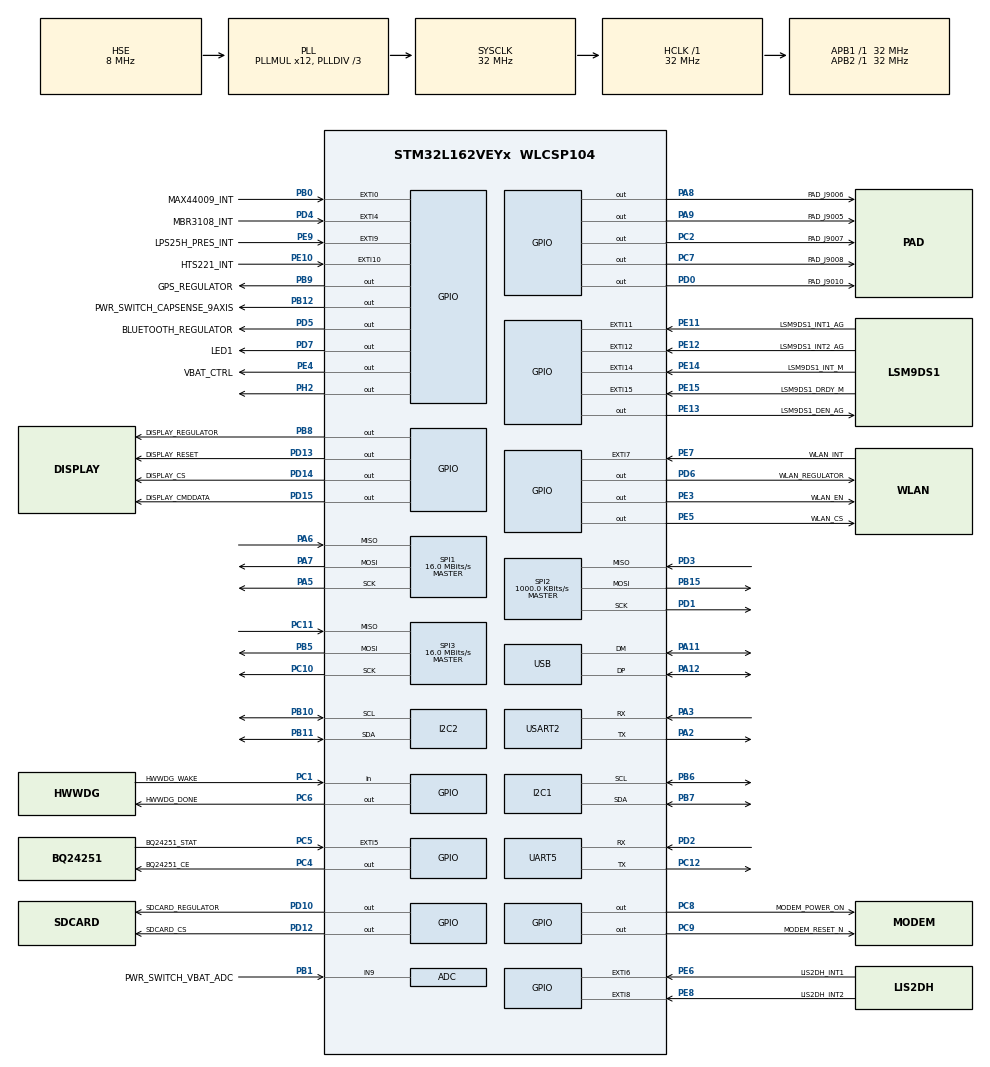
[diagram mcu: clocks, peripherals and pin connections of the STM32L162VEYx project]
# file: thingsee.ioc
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ADC.Channel-0\#ChannelRegularConversion=ADC_CHANNEL_9
ADC.NbrOfConversionFlag=1
ADC.Rank-0\#ChannelRegularConversion=1
ADC.SamplingTime-0\#ChannelRegularConversion=ADC_SAMPLETIME_4CYCLES
Mcu.Family=STM32L1
Mcu.Name=STM32L162VEYx
Mcu.Package=WLCSP104
NVIC.PriorityGroup=NVIC_PRIORITYGROUP_4
NVIC.USB_LP_IRQn=true\:0\:0\:false\:false\:true\:false
PA11.Mode=Device
PA11.Signal=USB_DM
PA12.Mode=Device
PA12.Signal=USB_DP
PA2.Mode=Asynchronous
PA2.Signal=USART2_TX
PA3.Mode=Asynchronous
PA3.Signal=USART2_RX
PA5.Mode=Full_Duplex_Master
PA5.Signal=SPI1_SCK
PA6.Mode=Full_Duplex_Master
PA6.Signal=SPI1_MISO
PA7.Mode=Full_Duplex_Master
PA7.Signal=SPI1_MOSI
PA8.GPIO_Label=PAD_J9006
PA8.GPIO_Speed=GPIO_SPEED_FREQ_HIGH
PA8.Signal=GPIO_Output
PA9.GPIO_Label=PAD_J9005
PA9.GPIO_Speed=GPIO_SPEED_FREQ_HIGH
PA9.Signal=GPIO_Output
PB0.GPIO_Label=MAX44009_INT
PB0.Signal=GPXTI0
PB1.GPIO_Label=PWR_SWITCH_VBAT_ADC
PB1.Mode=IN9
PB1.Signal=ADC_IN9
PB10.Mode=I2C
PB10.Signal=I2C2_SCL
PB11.Mode=I2C
PB11.Signal=I2C2_SDA
PB12.GPIO_Label=PWR_SWITCH_CAPSENSE_9AXIS
PB12.GPIO_Speed=GPIO_SPEED_FREQ_HIGH
PB12.Signal=GPIO_Output
PB15.Mode=Full_Duplex_Master
PB15.Signal=SPI2_MOSI
PB5.Mode=Full_Duplex_Master
PB5.Signal=SPI3_MOSI
PB6.Mode=I2C
PB6.Signal=I2C1_SCL
PB7.Mode=I2C
PB7.Signal=I2C1_SDA
PB8.GPIO_Label=DISPLAY_REGULATOR
PB8.GPIO_Speed=GPIO_SPEED_FREQ_HIGH
PB8.Signal=GPIO_Output
PB9.GPIO_Label=GPS_REGULATOR
PB9.GPIO_Speed=GPIO_SPEED_FREQ_HIGH
PB9.Signal=GPIO_Output
PC1.GPIO_Label=HWWDG_WAKE
PC1.Signal=GPIO_Input
PC10.Mode=Full_Duplex_Master
PC10.Signal=SPI3_SCK
PC11.Mode=Full_Duplex_Master
PC11.Signal=SPI3_MISO
PC12.Mode=Asynchronous
PC12.Signal=UART5_TX
PC14-OSC32_IN.Mode=LSE-External-Oscillator
PC14-OSC32_IN.Signal=RCC_OSC32_IN
PC15-OSC32_OUT.Mode=LSE-External-Oscillator
PC15-OSC32_OUT.Signal=RCC_OSC32_OUT
PC2.GPIO_Label=PAD_J9007
PC2.GPIO_Speed=GPIO_SPEED_FREQ_HIGH
PC2.Signal=GPIO_Output
PC4.GPIO_Label=BQ24251_CE
PC4.GPIO_Speed=GPIO_SPEED_FREQ_HIGH
PC4.Signal=GPIO_Output
PC5.GPIO_Label=BQ24251_STAT
PC5.Signal=GPXTI5
PC6.GPIO_Label=HWWDG_DONE
PC6.GPIO_Speed=GPIO_SPEED_FREQ_HIGH
PC6.Signal=GPIO_Output
PC7.GPIO_Label=PAD_J9008
PC7.GPIO_Speed=GPIO_SPEED_FREQ_HIGH
PC7.Signal=GPIO_Output
PC8.GPIO_Label=MODEM_POWER_ON
PC8.GPIO_ModeDefaultOutputPP=GPIO_MODE_OUTPUT_OD
PC8.GPIO_Speed=GPIO_SPEED_FREQ_HIGH
PC8.PinState=GPIO_PIN_SET
PC8.Signal=GPIO_Output
PC9.GPIO_Label=MODEM_RESET_N
PC9.GPIO_ModeDefaultOutputPP=GPIO_MODE_OUTPUT_OD
PC9.GPIO_Speed=GPIO_SPEED_FREQ_HIGH
PC9.PinState=GPIO_PIN_SET
PC9.Signal=GPIO_Output
PD0.GPIO_Label=PAD_J9010
PD0.GPIO_Speed=GPIO_SPEED_FREQ_HIGH
PD0.Signal=GPIO_Output
PD1.Mode=Full_Duplex_Master
PD1.Signal=SPI2_SCK
PD10.GPIO_Label=SDCARD_REGULATOR
PD10.GPIO_Speed=GPIO_SPEED_FREQ_HIGH
PD10.Signal=GPIO_Output
PD12.GPIO_Label=SDCARD_CS
PD12.GPIO_Speed=GPIO_SPEED_FREQ_HIGH
PD12.PinState=GPIO_PIN_SET
PD12.Signal=GPIO_Output
PD13.GPIO_Label=DISPLAY_RESET
PD13.GPIO_Speed=GPIO_SPEED_FREQ_HIGH
PD13.Signal=GPIO_Output
PD14.GPIO_Label=DISPLAY_CS
PD14.GPIO_Speed=GPIO_SPEED_FREQ_HIGH
PD14.PinState=GPIO_PIN_SET
PD14.Signal=GPIO_Output
PD15.GPIO_Label=DISPLAY_CMDDATA
PD15.GPIO_Speed=GPIO_SPEED_FREQ_HIGH
PD15.Signal=GPIO_Output
PD2.Mode=Asynchronous
PD2.Signal=UART5_RX
PD3.Mode=Full_Duplex_Master
PD3.Signal=SPI2_MISO
PD4.GPIO_Label=MBR3108_INT
PD4.Signal=GPXTI4
PD5.GPIO_Label=BLUETOOTH_REGULATOR
PD5.GPIO_Speed=GPIO_SPEED_FREQ_HIGH
PD5.Signal=GPIO_Output
PD6.GPIO_Label=WLAN_REGULATOR
PD6.GPIO_Speed=GPIO_SPEED_FREQ_HIGH
PD6.Signal=GPIO_Output
PD7.GPIO_Label=LED1
PD7.GPIO_Speed=GPIO_SPEED_FREQ_HIGH
PD7.Signal=GPIO_Output
PE10.GPIO_Label=HTS221_INT
PE10.Signal=GPXTI10
PE11.GPIO_Label=LSM9DS1_INT1_AG
PE11.Signal=GPXTI11
PE12.GPIO_Label=LSM9DS1_INT2_AG
PE12.Signal=GPXTI12
PE13.GPIO_Label=LSM9DS1_DEN_AG
PE13.GPIO_Speed=GPIO_SPEED_FREQ_HIGH
PE13.Signal=GPIO_Output
PE14.GPIO_Label=LSM9DS1_INT_M
PE14.Signal=GPXTI14
PE15.GPIO_Label=LSM9DS1_DRDY_M
PE15.Signal=GPXTI15
PE3.GPIO_Label=WLAN_EN
PE3.GPIO_Speed=GPIO_SPEED_FREQ_HIGH
PE3.Signal=GPIO_Output
PE4.GPIO_Label=VBAT_CTRL
PE4.GPIO_Speed=GPIO_SPEED_FREQ_HIGH
PE4.Signal=GPIO_Output
PE5.GPIO_Label=WLAN_CS
PE5.GPIO_Speed=GPIO_SPEED_FREQ_HIGH
PE5.PinState=GPIO_PIN_SET
PE5.Signal=GPIO_Output
PE6-WKUP3.GPIO_Label=LIS2DH_INT1
PE6-WKUP3.Signal=GPXTI6
PE7.GPIO_Label=WLAN_INT
PE7.Signal=GPXTI7
PE8.GPIO_Label=LIS2DH_INT2
PE8.Signal=GPXTI8
PE9.GPIO_Label=LPS25H_PRES_INT
PE9.Signal=GPXTI9
PH0-OSC_IN.Mode=HSE-External-Oscillator
PH0-OSC_IN.Signal=RCC_OSC_IN
PH1-OSC_OUT.Mode=HSE-External-Oscillator
PH1-OSC_OUT.Signal=RCC_OSC_OUT
PH2.GPIO_Speed=GPIO_SPEED_FREQ_HIGH
PH2.Signal=GPIO_Output
ProjectManager.HeapSize=0x200
ProjectManager.StackSize=0x400
ProjectManager.TargetToolchain=Makefile
RCC.48MHZClocksFreq_Value=48000000
RCC.AHBFreq_Value=32000000
RCC.APB1Freq_Value=32000000
RCC.APB1TimFreq_Value=32000000
RCC.APB2Freq_Value=32000000
RCC.APB2TimFreq_Value=32000000
RCC.HCLKFreq_Value=32000000
RCC.HSE_VALUE=8000000
RCC.HSI_VALUE=16000000
RCC.MSI_VALUE=2097000
RCC.PLLDIV=RCC_PLL_DIV3
RCC.PLLMUL=RCC_PLL_MUL12
RCC.SYSCLKFreq_VALUE=32000000
RCC.SYSCLKSource=RCC_SYSCLKSOURCE_PLLCLK
RCC.VCOOutputFreq_Value=96000000
SPI1.CalculateBaudRate=16.0 MBits/s
SPI1.Direction=SPI_DIRECTION_2LINES
SPI1.Mode=SPI_MODE_MASTER
SPI1.VirtualType=VM_MASTER
SPI2.BaudRatePrescaler=SPI_BAUDRATEPRESCALER_32
SPI2.CLKPhase=SPI_PHASE_1EDGE
SPI2.CLKPolarity=SPI_POLARITY_HIGH
SPI2.CalculateBaudRate=1000.0 KBits/s
SPI2.Direction=SPI_DIRECTION_2LINES
SPI2.Mode=SPI_MODE_MASTER
SPI2.VirtualType=VM_MASTER
SPI3.CalculateBaudRate=16.0 MBits/s
SPI3.Direction=SPI_DIRECTION_2LINES
SPI3.Mode=SPI_MODE_MASTER
SPI3.VirtualType=VM_MASTER
UART5.VirtualMode=Asynchronous
USART2.VirtualMode=VM_ASYNC
USB_DEVICE.CLASS_NAME_FS=CDC
USB_DEVICE.VirtualMode=Cdc
USB_DEVICE.VirtualModeFS=Cdc_FS
VP_ADC_TempSens_Input.Mode=IN-TempSens
VP_RTC_VS_RTC_Activate.Mode=RTC_Enabled
VP_USB_DEVICE_VS_USB_DEVICE_CDC_FS.Mode=CDC_FS
board=custom

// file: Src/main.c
/**
  ******************************************************************************
  * @file           : main.c
  * @brief          : Main program body
  ******************************************************************************
  * This notice applies to any and all portions of this file
  * that are not between comment pairs USER CODE BEGIN and
  * USER CODE END. Other portions of this file, whether
  * inserted by the user or by software development tools
  * are owned by their respective copyright owners.
  *
  * Copyright (c) 2018 STMicroelectronics International N.V.
  * All rights reserved.
  *
  * Redistribution and use in source and binary forms, with or without
  * modification, are permitted, provided that the following conditions are met:
  *
  * 1. Redistribution of source code must retain the above copyright notice,
  *    this list of conditions and the following disclaimer.
  * 2. Redistributions in binary form must reproduce the above copyright notice,
  *    this list of conditions and the following disclaimer in the documentation
  *    and/or other materials provided with the distribution.
  * 3. Neither the name of STMicroelectronics nor the names of other
  *    contributors to this software may be used to endorse or promote products
  *    derived from this software without specific written permission.
  * 4. This software, including modifications and/or derivative works of this
  *    software, must execute solely and exclusively on microcontroller or
  *    microprocessor devices manufactured by or for STMicroelectronics.
  * 5. Redistribution and use of this software other than as permitted under
  *    this license is void and will automatically terminate your rights under
  *    this license.
  *
  * THIS SOFTWARE IS PROVIDED BY STMICROELECTRONICS AND CONTRIBUTORS "AS IS"
  * AND ANY EXPRESS, IMPLIED OR STATUTORY WARRANTIES, INCLUDING, BUT NOT
  * LIMITED TO, THE IMPLIED WARRANTIES OF MERCHANTABILITY, FITNESS FOR A
  * PARTICULAR PURPOSE AND NON-INFRINGEMENT OF THIRD PARTY INTELLECTUAL PROPERTY
  * RIGHTS ARE DISCLAIMED TO THE FULLEST EXTENT PERMITTED BY LAW. IN NO EVENT
  * SHALL STMICROELECTRONICS OR CONTRIBUTORS BE LIABLE FOR ANY DIRECT, INDIRECT,
  * INCIDENTAL, SPECIAL, EXEMPLARY, OR CONSEQUENTIAL DAMAGES (INCLUDING, BUT NOT
  * LIMITED TO, PROCUREMENT OF SUBSTITUTE GOODS OR SERVICES; LOSS OF USE, DATA,
  * OR PROFITS; OR BUSINESS INTERRUPTION) HOWEVER CAUSED AND ON ANY THEORY OF
  * LIABILITY, WHETHER IN CONTRACT, STRICT LIABILITY, OR TORT (INCLUDING
  * NEGLIGENCE OR OTHERWISE) ARISING IN ANY WAY OUT OF THE USE OF THIS SOFTWARE,
  * EVEN IF ADVISED OF THE POSSIBILITY OF SUCH DAMAGE.
  *
  ******************************************************************************
  */
#include "main.h"
#include "stm32l1xx_hal.h"
#include "usb_device.h"

/* USER CODE BEGIN Includes */
#include "app.h"
/* USER CODE END Includes */

ADC_HandleTypeDef hadc;

I2C_HandleTypeDef hi2c1;
I2C_HandleTypeDef hi2c2;

RTC_HandleTypeDef hrtc;

SPI_HandleTypeDef hspi1;
SPI_HandleTypeDef hspi2;
SPI_HandleTypeDef hspi3;

UART_HandleTypeDef huart5;
UART_HandleTypeDef huart2;

/* USER CODE BEGIN PV */
/* Private variables ---------------------------------------------------------*/

/* USER CODE END PV */

void SystemClock_Config(void);
static void MX_GPIO_Init(void);
static void MX_ADC_Init(void);
static void MX_RTC_Init(void);
static void MX_I2C1_Init(void);
static void MX_I2C2_Init(void);
static void MX_USART2_UART_Init(void);
static void MX_UART5_Init(void);
static void MX_SPI2_Init(void);
static void MX_SPI1_Init(void);
static void MX_SPI3_Init(void);

/* USER CODE BEGIN PFP */
/* Private function prototypes -----------------------------------------------*/

/* USER CODE END PFP */

int main(void)
{

  /* MCU Configuration----------------------------------------------------------*/

  /* Reset of all peripherals, Initializes the Flash interface and the Systick. */
  HAL_Init();

  /* Configure the system clock */
  SystemClock_Config();

  /* Initialize all configured peripherals */
  MX_GPIO_Init();
  MX_ADC_Init();
  MX_RTC_Init();
  MX_USB_DEVICE_Init();
  MX_I2C1_Init();
  MX_I2C2_Init();
  MX_USART2_UART_Init();
  MX_UART5_Init();
  MX_SPI2_Init();
  MX_SPI1_Init();
  MX_SPI3_Init();
  /* USER CODE BEGIN 2 */

  setup();

  /* USER CODE END 2 */

  /* Infinite loop */
  while (1)
  {

  /* USER CODE BEGIN 3 */
    loop();
  }
  /* USER CODE END 3 */

}

void SystemClock_Config(void)
{

  RCC_OscInitTypeDef RCC_OscInitStruct;
  RCC_ClkInitTypeDef RCC_ClkInitStruct;
  RCC_PeriphCLKInitTypeDef PeriphClkInit;

    /**Configure the main internal regulator output voltage
    */
  __HAL_PWR_VOLTAGESCALING_CONFIG(PWR_REGULATOR_VOLTAGE_SCALE1);

    /**Initializes the CPU, AHB and APB busses clocks
    */
  RCC_OscInitStruct.OscillatorType = RCC_OSCILLATORTYPE_HSI|RCC_OSCILLATORTYPE_LSI
                              |RCC_OSCILLATORTYPE_HSE;
  RCC_OscInitStruct.HSEState = RCC_HSE_ON;
  RCC_OscInitStruct.HSIState = RCC_HSI_ON;
  RCC_OscInitStruct.HSICalibrationValue = 16;
  RCC_OscInitStruct.LSIState = RCC_LSI_ON;
  RCC_OscInitStruct.PLL.PLLState = RCC_PLL_ON;
  RCC_OscInitStruct.PLL.PLLSource = RCC_PLLSOURCE_HSE;
  RCC_OscInitStruct.PLL.PLLMUL = RCC_PLL_MUL12;
  RCC_OscInitStruct.PLL.PLLDIV = RCC_PLL_DIV3;
  if (HAL_RCC_OscConfig(&RCC_OscInitStruct) != HAL_OK)
  {
    _Error_Handler(__FILE__, __LINE__);
  }

    /**Initializes the CPU, AHB and APB busses clocks
    */
  RCC_ClkInitStruct.ClockType = RCC_CLOCKTYPE_HCLK|RCC_CLOCKTYPE_SYSCLK
                              |RCC_CLOCKTYPE_PCLK1|RCC_CLOCKTYPE_PCLK2;
  RCC_ClkInitStruct.SYSCLKSource = RCC_SYSCLKSOURCE_PLLCLK;
  RCC_ClkInitStruct.AHBCLKDivider = RCC_SYSCLK_DIV1;
  RCC_ClkInitStruct.APB1CLKDivider = RCC_HCLK_DIV1;
  RCC_ClkInitStruct.APB2CLKDivider = RCC_HCLK_DIV1;

  if (HAL_RCC_ClockConfig(&RCC_ClkInitStruct, FLASH_LATENCY_1) != HAL_OK)
  {
    _Error_Handler(__FILE__, __LINE__);
  }

  PeriphClkInit.PeriphClockSelection = RCC_PERIPHCLK_RTC;
  PeriphClkInit.RTCClockSelection = RCC_RTCCLKSOURCE_LSI;
  if (HAL_RCCEx_PeriphCLKConfig(&PeriphClkInit) != HAL_OK)
  {
    _Error_Handler(__FILE__, __LINE__);
  }

    /**Configure the Systick interrupt time
    */
  HAL_SYSTICK_Config(HAL_RCC_GetHCLKFreq()/1000);

    /**Configure the Systick
    */
  HAL_SYSTICK_CLKSourceConfig(SYSTICK_CLKSOURCE_HCLK);

  /* SysTick_IRQn interrupt configuration */
  HAL_NVIC_SetPriority(SysTick_IRQn, 0, 0);
}

/* ADC init function */
static void MX_ADC_Init(void)
{

  ADC_ChannelConfTypeDef sConfig;

    /**Configure the global features of the ADC (Clock, Resolution, Data Alignment and number of conversion)
    */
  hadc.Instance = ADC1;
  hadc.Init.ClockPrescaler = ADC_CLOCK_ASYNC_DIV1;
  hadc.Init.Resolution = ADC_RESOLUTION_12B;
  hadc.Init.DataAlign = ADC_DATAALIGN_RIGHT;
  hadc.Init.ScanConvMode = ADC_SCAN_DISABLE;
  hadc.Init.EOCSelection = ADC_EOC_SEQ_CONV;
  hadc.Init.LowPowerAutoWait = ADC_AUTOWAIT_DISABLE;
  hadc.Init.LowPowerAutoPowerOff = ADC_AUTOPOWEROFF_DISABLE;
  hadc.Init.ChannelsBank = ADC_CHANNELS_BANK_A;
  hadc.Init.ContinuousConvMode = DISABLE;
  hadc.Init.NbrOfConversion = 1;
  hadc.Init.DiscontinuousConvMode = DISABLE;
  hadc.Init.ExternalTrigConv = ADC_SOFTWARE_START;
  hadc.Init.ExternalTrigConvEdge = ADC_EXTERNALTRIGCONVEDGE_NONE;
  hadc.Init.DMAContinuousRequests = DISABLE;
  if (HAL_ADC_Init(&hadc) != HAL_OK)
  {
    _Error_Handler(__FILE__, __LINE__);
  }

    /**Configure for the selected ADC regular channel its corresponding rank in the sequencer and its sample time.
    */
  sConfig.Channel = ADC_CHANNEL_9;
  sConfig.Rank = ADC_REGULAR_RANK_1;
  sConfig.SamplingTime = ADC_SAMPLETIME_4CYCLES;
  if (HAL_ADC_ConfigChannel(&hadc, &sConfig) != HAL_OK)
  {
    _Error_Handler(__FILE__, __LINE__);
  }

}

/* I2C1 init function */
static void MX_I2C1_Init(void)
{

  hi2c1.Instance = I2C1;
  hi2c1.Init.ClockSpeed = 100000;
  hi2c1.Init.DutyCycle = I2C_DUTYCYCLE_2;
  hi2c1.Init.OwnAddress1 = 0;
  hi2c1.Init.AddressingMode = I2C_ADDRESSINGMODE_7BIT;
  hi2c1.Init.DualAddressMode = I2C_DUALADDRESS_DISABLE;
  hi2c1.Init.OwnAddress2 = 0;
  hi2c1.Init.GeneralCallMode = I2C_GENERALCALL_DISABLE;
  hi2c1.Init.NoStretchMode = I2C_NOSTRETCH_DISABLE;
  if (HAL_I2C_Init(&hi2c1) != HAL_OK)
  {
    _Error_Handler(__FILE__, __LINE__);
  }

}

/* I2C2 init function */
static void MX_I2C2_Init(void)
{

  hi2c2.Instance = I2C2;
  hi2c2.Init.ClockSpeed = 100000;
  hi2c2.Init.DutyCycle = I2C_DUTYCYCLE_2;
  hi2c2.Init.OwnAddress1 = 0;
  hi2c2.Init.AddressingMode = I2C_ADDRESSINGMODE_7BIT;
  hi2c2.Init.DualAddressMode = I2C_DUALADDRESS_DISABLE;
  hi2c2.Init.OwnAddress2 = 0;
  hi2c2.Init.GeneralCallMode = I2C_GENERALCALL_DISABLE;
  hi2c2.Init.NoStretchMode = I2C_NOSTRETCH_DISABLE;
  if (HAL_I2C_Init(&hi2c2) != HAL_OK)
  {
    _Error_Handler(__FILE__, __LINE__);
  }

}

/* RTC init function */
static void MX_RTC_Init(void)
{

    /**Initialize RTC Only
    */
  hrtc.Instance = RTC;
  hrtc.Init.HourFormat = RTC_HOURFORMAT_24;
  hrtc.Init.AsynchPrediv = 127;
  hrtc.Init.SynchPrediv = 255;
  hrtc.Init.OutPut = RTC_OUTPUT_DISABLE;
  hrtc.Init.OutPutPolarity = RTC_OUTPUT_POLARITY_HIGH;
  hrtc.Init.OutPutType = RTC_OUTPUT_TYPE_OPENDRAIN;
  if (HAL_RTC_Init(&hrtc) != HAL_OK)
  {
    _Error_Handler(__FILE__, __LINE__);
  }

}

/* SPI1 init function */
static void MX_SPI1_Init(void)
{

  /* SPI1 parameter configuration*/
  hspi1.Instance = SPI1;
  hspi1.Init.Mode = SPI_MODE_MASTER;
  hspi1.Init.Direction = SPI_DIRECTION_2LINES;
  hspi1.Init.DataSize = SPI_DATASIZE_8BIT;
  hspi1.Init.CLKPolarity = SPI_POLARITY_LOW;
  hspi1.Init.CLKPhase = SPI_PHASE_1EDGE;
  hspi1.Init.NSS = SPI_NSS_SOFT;
  hspi1.Init.BaudRatePrescaler = SPI_BAUDRATEPRESCALER_2;
  hspi1.Init.FirstBit = SPI_FIRSTBIT_MSB;
  hspi1.Init.TIMode = SPI_TIMODE_DISABLE;
  hspi1.Init.CRCCalculation = SPI_CRCCALCULATION_DISABLE;
  hspi1.Init.CRCPolynomial = 10;
  if (HAL_SPI_Init(&hspi1) != HAL_OK)
  {
    _Error_Handler(__FILE__, __LINE__);
  }

}

/* SPI2 init function */
static void MX_SPI2_Init(void)
{

  /* SPI2 parameter configuration*/
  hspi2.Instance = SPI2;
  hspi2.Init.Mode = SPI_MODE_MASTER;
  hspi2.Init.Direction = SPI_DIRECTION_2LINES;
  hspi2.Init.DataSize = SPI_DATASIZE_8BIT;
  hspi2.Init.CLKPolarity = SPI_POLARITY_HIGH;
  hspi2.Init.CLKPhase = SPI_PHASE_1EDGE;
  hspi2.Init.NSS = SPI_NSS_SOFT;
  hspi2.Init.BaudRatePrescaler = SPI_BAUDRATEPRESCALER_32;
  hspi2.Init.FirstBit = SPI_FIRSTBIT_MSB;
  hspi2.Init.TIMode = SPI_TIMODE_DISABLE;
  hspi2.Init.CRCCalculation = SPI_CRCCALCULATION_DISABLE;
  hspi2.Init.CRCPolynomial = 10;
  if (HAL_SPI_Init(&hspi2) != HAL_OK)
  {
    _Error_Handler(__FILE__, __LINE__);
  }

}

/* SPI3 init function */
static void MX_SPI3_Init(void)
{

  /* SPI3 parameter configuration*/
  hspi3.Instance = SPI3;
  hspi3.Init.Mode = SPI_MODE_MASTER;
  hspi3.Init.Direction = SPI_DIRECTION_2LINES;
  hspi3.Init.DataSize = SPI_DATASIZE_8BIT;
  hspi3.Init.CLKPolarity = SPI_POLARITY_LOW;
  hspi3.Init.CLKPhase = SPI_PHASE_1EDGE;
  hspi3.Init.NSS = SPI_NSS_SOFT;
  hspi3.Init.BaudRatePrescaler = SPI_BAUDRATEPRESCALER_2;
  hspi3.Init.FirstBit = SPI_FIRSTBIT_MSB;
  hspi3.Init.TIMode = SPI_TIMODE_DISABLE;
  hspi3.Init.CRCCalculation = SPI_CRCCALCULATION_DISABLE;
  hspi3.Init.CRCPolynomial = 10;
  if (HAL_SPI_Init(&hspi3) != HAL_OK)
  {
    _Error_Handler(__FILE__, __LINE__);
  }

}

/* UART5 init function */
static void MX_UART5_Init(void)
{

  huart5.Instance = UART5;
  huart5.Init.BaudRate = 115200;
  huart5.Init.WordLength = UART_WORDLENGTH_8B;
  huart5.Init.StopBits = UART_STOPBITS_1;
  huart5.Init.Parity = UART_PARITY_NONE;
  huart5.Init.Mode = UART_MODE_TX_RX;
  huart5.Init.HwFlowCtl = UART_HWCONTROL_NONE;
  huart5.Init.OverSampling = UART_OVERSAMPLING_16;
  if (HAL_UART_Init(&huart5) != HAL_OK)
  {
    _Error_Handler(__FILE__, __LINE__);
  }

}

/* USART2 init function */
static void MX_USART2_UART_Init(void)
{

  huart2.Instance = USART2;
  huart2.Init.BaudRate = 115200;
  huart2.Init.WordLength = UART_WORDLENGTH_8B;
  huart2.Init.StopBits = UART_STOPBITS_1;
  huart2.Init.Parity = UART_PARITY_NONE;
  huart2.Init.Mode = UART_MODE_TX_RX;
  huart2.Init.HwFlowCtl = UART_HWCONTROL_NONE;
  huart2.Init.OverSampling = UART_OVERSAMPLING_16;
  if (HAL_UART_Init(&huart2) != HAL_OK)
  {
    _Error_Handler(__FILE__, __LINE__);
  }

}

/** Configure pins as
        * Analog
        * Input
        * Output
        * EVENT_OUT
        * EXTI
*/
static void MX_GPIO_Init(void)
{

  GPIO_InitTypeDef GPIO_InitStruct;

  /* GPIO Ports Clock Enable */
  __HAL_RCC_GPIOD_CLK_ENABLE();
  __HAL_RCC_GPIOB_CLK_ENABLE();
  __HAL_RCC_GPIOC_CLK_ENABLE();
  __HAL_RCC_GPIOE_CLK_ENABLE();
  __HAL_RCC_GPIOH_CLK_ENABLE();
  __HAL_RCC_GPIOA_CLK_ENABLE();

  /*Configure GPIO pin Output Level */
  HAL_GPIO_WritePin(GPIOD, PAD_J9010_Pin|LED1_Pin|BLUETOOTH_REGULATOR_Pin|WLAN_REGULATOR_Pin
                          |DISPLAY_CMDDATA_Pin|DISPLAY_RESET_Pin|SDCARD_REGULATOR_Pin, GPIO_PIN_RESET);

  /*Configure GPIO pin Output Level */
  HAL_GPIO_WritePin(WLAN_CS_GPIO_Port, WLAN_CS_Pin, GPIO_PIN_SET);

  /*Configure GPIO pin Output Level */
  HAL_GPIO_WritePin(GPIOB, GPS_REGULATOR_Pin|DISPLAY_REGULATOR_Pin|PWR_SWITCH_CAPSENSE_9AXIS_Pin, GPIO_PIN_RESET);

  /*Configure GPIO pin Output Level */
  HAL_GPIO_WritePin(GPIOE, VBAT_CTRL_Pin|WLAN_EN_Pin|LSM9DS1_DEN_AG_Pin, GPIO_PIN_RESET);

  /*Configure GPIO pin Output Level */
  HAL_GPIO_WritePin(GPIOH, GPIO_PIN_2, GPIO_PIN_RESET);

  /*Configure GPIO pin Output Level */
  HAL_GPIO_WritePin(GPIOA, PAD_J9005_Pin|PAD_J9006_Pin, GPIO_PIN_RESET);

  /*Configure GPIO pin Output Level */
  HAL_GPIO_WritePin(GPIOC, MODEM_RESET_N_Pin|MODEM_POWER_ON_Pin, GPIO_PIN_SET);

  /*Configure GPIO pin Output Level */
  HAL_GPIO_WritePin(GPIOC, PAD_J9008_Pin|PAD_J9007_Pin|HWWDG_DONE_Pin|BQ24251_CE_Pin, GPIO_PIN_RESET);

  /*Configure GPIO pin Output Level */
  HAL_GPIO_WritePin(GPIOD, SDCARD_CS_Pin|DISPLAY_CS_Pin, GPIO_PIN_SET);

  /*Configure GPIO pins : PAD_J9010_Pin LED1_Pin BLUETOOTH_REGULATOR_Pin WLAN_REGULATOR_Pin
                           DISPLAY_CMDDATA_Pin DISPLAY_RESET_Pin SDCARD_CS_Pin DISPLAY_CS_Pin
                           SDCARD_REGULATOR_Pin */
  GPIO_InitStruct.Pin = PAD_J9010_Pin|LED1_Pin|BLUETOOTH_REGULATOR_Pin|WLAN_REGULATOR_Pin
                          |DISPLAY_CMDDATA_Pin|DISPLAY_RESET_Pin|SDCARD_CS_Pin|DISPLAY_CS_Pin
                          |SDCARD_REGULATOR_Pin;
  GPIO_InitStruct.Mode = GPIO_MODE_OUTPUT_PP;
  GPIO_InitStruct.Pull = GPIO_NOPULL;
  GPIO_InitStruct.Speed = GPIO_SPEED_FREQ_HIGH;
  HAL_GPIO_Init(GPIOD, &GPIO_InitStruct);

  /*Configure GPIO pin : MBR3108_INT_Pin */
  GPIO_InitStruct.Pin = MBR3108_INT_Pin;
  GPIO_InitStruct.Mode = GPIO_MODE_IT_RISING;
  GPIO_InitStruct.Pull = GPIO_NOPULL;
  HAL_GPIO_Init(MBR3108_INT_GPIO_Port, &GPIO_InitStruct);

  /*Configure GPIO pins : WLAN_CS_Pin VBAT_CTRL_Pin WLAN_EN_Pin LSM9DS1_DEN_AG_Pin */
  GPIO_InitStruct.Pin = WLAN_CS_Pin|VBAT_CTRL_Pin|WLAN_EN_Pin|LSM9DS1_DEN_AG_Pin;
  GPIO_InitStruct.Mode = GPIO_MODE_OUTPUT_PP;
  GPIO_InitStruct.Pull = GPIO_NOPULL;
  GPIO_InitStruct.Speed = GPIO_SPEED_FREQ_HIGH;
  HAL_GPIO_Init(GPIOE, &GPIO_InitStruct);

  /*Configure GPIO pins : GPS_REGULATOR_Pin DISPLAY_REGULATOR_Pin PWR_SWITCH_CAPSENSE_9AXIS_Pin */
  GPIO_InitStruct.Pin = GPS_REGULATOR_Pin|DISPLAY_REGULATOR_Pin|PWR_SWITCH_CAPSENSE_9AXIS_Pin;
  GPIO_InitStruct.Mode = GPIO_MODE_OUTPUT_PP;
  GPIO_InitStruct.Pull = GPIO_NOPULL;
  GPIO_InitStruct.Speed = GPIO_SPEED_FREQ_HIGH;
  HAL_GPIO_Init(GPIOB, &GPIO_InitStruct);

  /*Configure GPIO pin : PH2 */
  GPIO_InitStruct.Pin = GPIO_PIN_2;
  GPIO_InitStruct.Mode = GPIO_MODE_OUTPUT_PP;
  GPIO_InitStruct.Pull = GPIO_NOPULL;
  GPIO_InitStruct.Speed = GPIO_SPEED_FREQ_HIGH;
  HAL_GPIO_Init(GPIOH, &GPIO_InitStruct);

  /*Configure GPIO pins : LIS2DH_INT1_Pin HTS221_INT_Pin LSM9DS1_DRDY_M_Pin LSM9DS1_INT_M_Pin
                           LSM9DS1_INT1_AG_Pin WLAN_INT_Pin LSM9DS1_INT2_AG_Pin LPS25H_PRES_INT_Pin
                           LIS2DH_INT2_Pin */
  GPIO_InitStruct.Pin = LIS2DH_INT1_Pin|HTS221_INT_Pin|LSM9DS1_DRDY_M_Pin|LSM9DS1_INT_M_Pin
                          |LSM9DS1_INT1_AG_Pin|WLAN_INT_Pin|LSM9DS1_INT2_AG_Pin|LPS25H_PRES_INT_Pin
                          |LIS2DH_INT2_Pin;
  GPIO_InitStruct.Mode = GPIO_MODE_IT_RISING;
  GPIO_InitStruct.Pull = GPIO_NOPULL;
  HAL_GPIO_Init(GPIOE, &GPIO_InitStruct);

  /*Configure GPIO pins : PAD_J9005_Pin PAD_J9006_Pin */
  GPIO_InitStruct.Pin = PAD_J9005_Pin|PAD_J9006_Pin;
  GPIO_InitStruct.Mode = GPIO_MODE_OUTPUT_PP;
  GPIO_InitStruct.Pull = GPIO_NOPULL;
  GPIO_InitStruct.Speed = GPIO_SPEED_FREQ_HIGH;
  HAL_GPIO_Init(GPIOA, &GPIO_InitStruct);

  /*Configure GPIO pins : MODEM_RESET_N_Pin MODEM_POWER_ON_Pin */
  GPIO_InitStruct.Pin = MODEM_RESET_N_Pin|MODEM_POWER_ON_Pin;
  GPIO_InitStruct.Mode = GPIO_MODE_OUTPUT_OD;
  GPIO_InitStruct.Pull = GPIO_NOPULL;
  GPIO_InitStruct.Speed = GPIO_SPEED_FREQ_HIGH;
  HAL_GPIO_Init(GPIOC, &GPIO_InitStruct);

  /*Configure GPIO pins : PAD_J9008_Pin PAD_J9007_Pin HWWDG_DONE_Pin BQ24251_CE_Pin */
  GPIO_InitStruct.Pin = PAD_J9008_Pin|PAD_J9007_Pin|HWWDG_DONE_Pin|BQ24251_CE_Pin;
  GPIO_InitStruct.Mode = GPIO_MODE_OUTPUT_PP;
  GPIO_InitStruct.Pull = GPIO_NOPULL;
  GPIO_InitStruct.Speed = GPIO_SPEED_FREQ_HIGH;
  HAL_GPIO_Init(GPIOC, &GPIO_InitStruct);

  /*Configure GPIO pin : HWWDG_WAKE_Pin */
  GPIO_InitStruct.Pin = HWWDG_WAKE_Pin;
  GPIO_InitStruct.Mode = GPIO_MODE_INPUT;
  GPIO_InitStruct.Pull = GPIO_NOPULL;
  HAL_GPIO_Init(HWWDG_WAKE_GPIO_Port, &GPIO_InitStruct);

  /*Configure GPIO pin : MAX44009_INT_Pin */
  GPIO_InitStruct.Pin = MAX44009_INT_Pin;
  GPIO_InitStruct.Mode = GPIO_MODE_IT_RISING;
  GPIO_InitStruct.Pull = GPIO_NOPULL;
  HAL_GPIO_Init(MAX44009_INT_GPIO_Port, &GPIO_InitStruct);

  /*Configure GPIO pin : BQ24251_STAT_Pin */
  GPIO_InitStruct.Pin = BQ24251_STAT_Pin;
  GPIO_InitStruct.Mode = GPIO_MODE_IT_RISING;
  GPIO_InitStruct.Pull = GPIO_NOPULL;
  HAL_GPIO_Init(BQ24251_STAT_GPIO_Port, &GPIO_InitStruct);

}

void _Error_Handler(char *file, int line)
{
  while (1)
  {
  }
}

/************************ (C) COPYRIGHT STMicroelectronics *****END OF FILE****/
